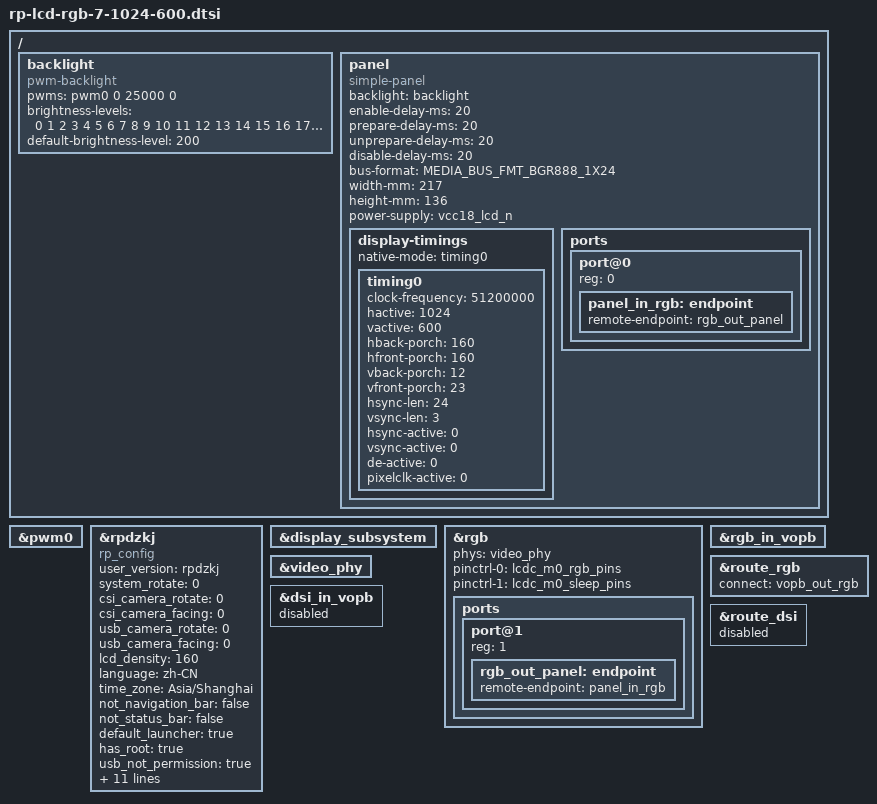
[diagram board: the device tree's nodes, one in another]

/{
	backlight: backlight {
		compatible = "pwm-backlight";
		pwms = <&pwm0 0 25000 0>;
		brightness-levels = <
			  0   1   2   3   4   5   6   7
			  8   9  10  11  12  13  14  15
			 16  17  18  19  20  21  22  23
			 24  25  26  27  28  29  30  31
			 32  33  34  35  36  37  38  39
			 40  41  42  43  44  45  46  47
			 48  49  50  51  52  53  54  55
			 56  57  58  59  60  61  62  63
			 64  65  66  67  68  69  70  71
			 72  73  74  75  76  77  78  79
			 80  81  82  83  84  85  86  87
			 88  89  90  91  92  93  94  95
			 96  97  98  99 100 101 102 103
			104 105 106 107 108 109 110 111
			112 113 114 115 116 117 118 119
			120 121 122 123 124 125 126 127
			128 129 130 131 132 133 134 135
			136 137 138 139 140 141 142 143
			144 145 146 147 148 149 150 151
			152 153 154 155 156 157 158 159
			160 161 162 163 164 165 166 167
			168 169 170 171 172 173 174 175
			176 177 178 179 180 181 182 183
			184 185 186 187 188 189 190 191
			192 193 194 195 196 197 198 199
			200 201 202 203 204 205 206 207
			208 209 210 211 212 213 214 215
			216 217 218 219 220 221 222 223
			224 225 226 227 228 229 230 231
			232 233 234 235 236 237 238 239
			240 241 242 243 244 245 246 247
			248 249 250 251 252 253 254 255>;
		default-brightness-level = <200>;
	};
	
	
		
	panel {
	    status = "okay";
	    compatible = "simple-panel";
	    backlight = <&backlight>;
	
	    enable-delay-ms = <20>;
	    prepare-delay-ms = <20>;
	    unprepare-delay-ms = <20>;
	    disable-delay-ms = <20>;
	    //bus-format = <MEDIA_BUS_FMT_RGB666_1X18>;
	    bus-format = <MEDIA_BUS_FMT_BGR888_1X24>;
	
	    width-mm = <217>;
	    height-mm = <136>;
	
	    /**
	     * power-supply = <>;
	     * reset-gpios = <>;
	     *
	     * lcd reset pin and power supply
	     * please refer to ***-lcd-gpio.dtsi
	     * that included in main dts.
	     */
	    power-supply = <&vcc18_lcd_n>;
	    //enable-gpios = <&gpio0 RK_PC0 GPIO_ACTIVE_HIGH>;
	    //reset-gpios = <&gpio0 RK_PC4 GPIO_ACTIVE_LOW>;
	
	    display-timings {
		native-mode = <&timing0>;

		timing0: timing0 {
			clock-frequency = <51200000>;
			hactive = <1024>;
			vactive = <600>;
			hback-porch = <160>;
			hfront-porch = <160>;
			vback-porch = <12>;
			vfront-porch = <23>;
			hsync-len = <24>;
			vsync-len = <3>;
			hsync-active = <0>;
			vsync-active = <0>;
			de-active = <0>;
			pixelclk-active = <0>;
		};
	    };
	    
	    ports {
	      	#address-cells = <1>;
	      	#size-cells = <0>;
	      	
		port@0 {
			reg = <0>;
			panel_in_rgb: endpoint {
				remote-endpoint = <&rgb_out_panel>;
			};
	        };
	    };
	};
};

&pwm0 {
       status = "okay";
};


&rpdzkj {
        compatible = "rp_config";
        user_version = "rpdzkj";
        system_rotate = "0";
        csi_camera_rotate = "0"; //all csi camera rotation //0 90 180 270 //no effect
        csi_camera_facing = "0"; //0:auto  1:all front   2:all back //no effect
        usb_camera_rotate = "0"; //all usb camera rotation //0 90 180 270 
        usb_camera_facing = "0"; //0:auto  1:all front   2:all back
        lcd_density = "160";
        language = "zh-CN";   //zh-CN //en-US
        time_zone = "Asia/Shanghai"; //Asia/Shanghai = +8   //Europe/London  = +1       //Africa/Casablanca     = +0;
        not_navigation_bar = "false";
        not_status_bar = "false";
        default_launcher = "true";
        has_root = "true";
        usb_not_permission = "true";
        gps_use = "false";
        gps_serial_port = "/dev/ttyS4";
        primary_device = "RGB";
        extend_device = "HDMI-A";
        extend_rotate = "0";//0 0//1 90 //2 180 //3 270
        rotation_efull = "false";
        extend_rotate_2 = "0";//0 0//1 90 //2 180 //3 270
        rotation_efull_2 = "true";
        extend_rotate_3 = "0";//0 0//1 90 //2 180 //3 270
        rotation_efull_3 = "true";
        home_apk = "null";
        status = "okay";
};


&display_subsystem {
	status = "okay";
};

&rgb {
	status = "okay";
	phys = <&video_phy>;
 	phy-names = "phy";
	pinctrl-names = "default", "sleep";
	pinctrl-0 = <&lcdc_m0_rgb_pins>;
	pinctrl-1 = <&lcdc_m0_sleep_pins>;
	


        
};


&rgb {
	status = "okay";

	ports {
		port@1 {
			reg = <1>;

			rgb_out_panel: endpoint {
				remote-endpoint = <&panel_in_rgb>;
			};
		};
	};
};

&rgb_in_vopb {
	status = "okay";
	
	
};

&video_phy {
	status = "okay";
};

&route_rgb {
	connect = <&vopb_out_rgb>;
	status = "okay";
};

&dsi_in_vopb {
        status = "disabled";
};

&route_dsi {
        status = "disabled";
};

// TP
//&i2c1 {
//        status = "okay";
//        clock-frequency = <200000>;
//	
//    	gt9xx: goodix_ts@5d {
//        	/***** tp pin ******/
//     		pinctrl-names = "default";
//       		pinctrl-0 = <&goodix_irq>;
//        	goodix_rst_gpio = <&gpio0 RK_PB4 GPIO_ACTIVE_HIGH>;
//        	goodix_irq_gpio = <&gpio0 RK_PB5 IRQ_TYPE_EDGE_FALLING>;
//
//		status = "okay";
//		compatible = "goodix,gt9xx";
//		reg = <0x5d>;
//		gtp_resolution_x = <1024>;
//		gtp_resolution_y = <600>;
//		gtp_int_tarigger = <1>;
//		gtp_change_x2y = <0>;
//		gtp_overturn_x = <0>;
//		gtp_overturn_y = <0>;
//		gtp_send_cfg = <1>;
//		gtp_touch_wakeup = <1>;
//		
//		/**
//		 * goodix_rst_gpio = <>;
//		 * goodix_irq_gpio = <>;
//		 *
//		 * touch panel interrupt and reset pin
//		 * please refer to ***-lcd-gpio.dtsi
//		 * that included in main dts.
//		 */
//
//        goodix,cfg-group0 = [
//            46 00 04 58 02 0A 3D 00 01 08
//            28 05 50 32 03 05 00 00 00 00
//            00 00 00 18 1A 1E 14 8D 2D 88
//            17 15 31 0D 00 00 01 9B 03 1D
//            00 00 00 00 00 00 00 00 00 00
//            00 1E 5A 94 C5 02 08 00 00 00
//            61 21 00 57 29 00 4E 34 00 48
//            41 00 43 51 00 43 00 00 00 00
//            00 00 00 00 00 00 00 00 00 00
//            00 00 00 00 00 00 00 00 00 00
//            00 00 00 00 00 00 00 00 00 00
//            00 00 00 01 04 05 06 07 08 09
//            0C 0D 0E 0F 10 11 14 15 FF FF
//            FF FF 00 00 00 00 00 00 00 00
//            00 00 00 02 04 06 07 08 0A 0C
//            0F 10 11 12 13 19 1B 1C 1E 1F
//            20 21 22 23 24 25 26 27 FF FF
//            FF FF FF FF 00 00 00 00 00 00
//            00 00 00 00 FD 01
//		];
//
//
//        goodix,cfg-group1 = [
//            46 00 04 58 02 0A 3D 00 01 08
//            28 05 50 32 03 05 00 00 00 00
//            00 00 00 18 1A 1E 14 8D 2D 88
//            17 15 31 0D 00 00 01 9B 03 1D
//            00 00 00 00 00 00 00 00 00 00
//            00 1E 5A 94 C5 02 08 00 00 00
//            61 21 00 57 29 00 4E 34 00 48
//            41 00 43 51 00 43 00 00 00 00
//            00 00 00 00 00 00 00 00 00 00
//            00 00 00 00 00 00 00 00 00 00
//            00 00 00 00 00 00 00 00 00 00
//            00 00 00 01 04 05 06 07 08 09
//            0C 0D 0E 0F 10 11 14 15 FF FF
//            FF FF 00 00 00 00 00 00 00 00
//            00 00 00 02 04 06 07 08 0A 0C
//            0F 10 11 12 13 19 1B 1C 1E 1F
//            20 21 22 23 24 25 26 27 FF FF
//            FF FF FF FF 00 00 00 00 00 00
//            00 00 00 00 FD 01
//		];
//		
//		goodix,cfg-group3 = [
//            46 00 04 58 02 0A 3D 00 01 08
//            28 05 50 32 03 05 00 00 00 00
//            00 00 00 18 1A 1E 14 8D 2D 88
//            17 15 31 0D 00 00 01 9B 03 1D
//            00 00 00 00 00 00 00 00 00 00
//            00 1E 5A 94 C5 02 08 00 00 00
//            61 21 00 57 29 00 4E 34 00 48
//            41 00 43 51 00 43 00 00 00 00
//            00 00 00 00 00 00 00 00 00 00
//            00 00 00 00 00 00 00 00 00 00
//            00 00 00 00 00 00 00 00 00 00
//            00 00 00 01 04 05 06 07 08 09
//            0C 0D 0E 0F 10 11 14 15 FF FF
//            FF FF 00 00 00 00 00 00 00 00
//            00 00 00 02 04 06 07 08 0A 0C
//            0F 10 11 12 13 19 1B 1C 1E 1F
//            20 21 22 23 24 25 26 27 FF FF
//            FF FF FF FF 00 00 00 00 00 00
//            00 00 00 00 FD 01
//		];
//    };
//};
//
//
//&pinctrl {
//    goodix {
//        goodix_irq: goodix-irq {
//            rockchip,pins = <0 RK_PB5 RK_FUNC_GPIO &pcfg_pull_up>;
//        };
//    };
//};

